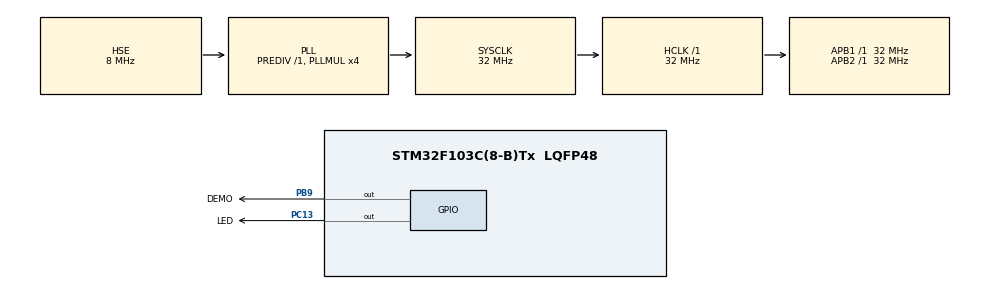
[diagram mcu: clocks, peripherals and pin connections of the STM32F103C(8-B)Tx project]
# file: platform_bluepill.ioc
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Mcu.Family=STM32F1
Mcu.Name=STM32F103C(8-B)Tx
Mcu.Package=LQFP48
NVIC.PriorityGroup=NVIC_PRIORITYGROUP_4
NVIC.TIM1_UP_IRQn=true\:0\:0\:false\:false\:true\:true\:true
PA13.Mode=Serial_Wire
PA13.Signal=SYS_JTMS-SWDIO
PA14.Mode=Serial_Wire
PA14.Signal=SYS_JTCK-SWCLK
PB9.GPIO_Label=DEMO
PB9.GPIO_ModeDefaultOutputPP=GPIO_MODE_OUTPUT_OD
PB9.GPIO_Speed=GPIO_SPEED_FREQ_HIGH
PB9.Signal=GPIO_Output
PC13-TAMPER-RTC.GPIO_Label=LED
PC13-TAMPER-RTC.GPIO_Speed=GPIO_SPEED_FREQ_LOW
PC13-TAMPER-RTC.Signal=GPIO_Output
PC14-OSC32_IN.Mode=LSE-External-Oscillator
PC14-OSC32_IN.Signal=RCC_OSC32_IN
PC15-OSC32_OUT.Mode=LSE-External-Oscillator
PC15-OSC32_OUT.Signal=RCC_OSC32_OUT
PD0-OSC_IN.Mode=HSE-External-Oscillator
PD0-OSC_IN.Signal=RCC_OSC_IN
PD1-OSC_OUT.Mode=HSE-External-Oscillator
PD1-OSC_OUT.Signal=RCC_OSC_OUT
ProjectManager.HeapSize=0x200
ProjectManager.StackSize=0x400
ProjectManager.TargetToolchain=Makefile
RCC.AHBFreq_Value=32000000
RCC.APB1Freq_Value=32000000
RCC.APB1TimFreq_Value=32000000
RCC.APB2Freq_Value=32000000
RCC.APB2TimFreq_Value=32000000
RCC.HCLKFreq_Value=32000000
RCC.PLLMUL=RCC_PLL_MUL4
RCC.PLLSourceVirtual=RCC_PLLSOURCE_HSE
RCC.SYSCLKFreq_VALUE=32000000
RCC.SYSCLKSource=RCC_SYSCLKSOURCE_PLLCLK
RCC.USBFreq_Value=32000000
TIM1.Period=61 - 3
TIM1.Prescaler=32
VP_TIM1_VS_ClockSourceINT.Mode=Internal
board=custom

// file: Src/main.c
/* USER CODE BEGIN Header */
/**
  ******************************************************************************
  * @file           : main.c
  * @brief          : Main program body
  ******************************************************************************
  * @attention
  *
  * <h2><center>&copy; Copyright (c) 2020 STMicroelectronics.
  * All rights reserved.</center></h2>
  *
  * This software component is licensed by ST under BSD 3-Clause license,
  * the "License"; You may not use this file except in compliance with the
  * License. You may obtain a copy of the License at:
  *                        opensource.org/licenses/BSD-3-Clause
  *
  ******************************************************************************
  */
/* USER CODE END Header */

#include "main.h"

TIM_HandleTypeDef htim1;

void SystemClock_Config(void);
static void MX_GPIO_Init(void);
static void MX_TIM1_Init(void);
/* USER CODE BEGIN PFP */

uint8_t handle_tick();
void init_render();

/* USER CODE END PFP */

/* USER CODE BEGIN 0 */
void HAL_TIM_PeriodElapsedCallback(TIM_HandleTypeDef *htim) {
  HAL_GPIO_TogglePin(DEMO_GPIO_Port, DEMO_Pin);

  if(handle_tick() > 0) {
    HAL_GPIO_WritePin(LED_GPIO_Port, LED_Pin, GPIO_PIN_SET);
  } else {
    HAL_GPIO_WritePin(LED_GPIO_Port, LED_Pin, GPIO_PIN_RESET);
  }
}
/* USER CODE END 0 */

int main(void)
{

  /* MCU Configuration--------------------------------------------------------*/

  /* Reset of all peripherals, Initializes the Flash interface and the Systick. */
  HAL_Init();

  /* Configure the system clock */
  SystemClock_Config();

  /* Initialize all configured peripherals */
  MX_GPIO_Init();
  MX_TIM1_Init();
  /* USER CODE BEGIN 2 */

  init_render();

  HAL_TIM_Base_Start_IT(&htim1);

  /* USER CODE END 2 */

  /* Infinite loop */
  while (1)
  {

    /* USER CODE BEGIN 3 */
    /*
    HAL_GPIO_WritePin(LED_GPIO_Port, LED_Pin, GPIO_PIN_SET);
    HAL_Delay(100);
    HAL_GPIO_WritePin(LED_GPIO_Port, LED_Pin, GPIO_PIN_RESET);
    HAL_Delay(100);
    */
  }
  /* USER CODE END 3 */
}

void SystemClock_Config(void)
{
  RCC_OscInitTypeDef RCC_OscInitStruct = {0};
  RCC_ClkInitTypeDef RCC_ClkInitStruct = {0};

  /** Initializes the CPU, AHB and APB busses clocks
  */
  RCC_OscInitStruct.OscillatorType = RCC_OSCILLATORTYPE_HSE;
  RCC_OscInitStruct.HSEState = RCC_HSE_ON;
  RCC_OscInitStruct.HSEPredivValue = RCC_HSE_PREDIV_DIV1;
  RCC_OscInitStruct.HSIState = RCC_HSI_ON;
  RCC_OscInitStruct.PLL.PLLState = RCC_PLL_ON;
  RCC_OscInitStruct.PLL.PLLSource = RCC_PLLSOURCE_HSE;
  RCC_OscInitStruct.PLL.PLLMUL = RCC_PLL_MUL4;
  if (HAL_RCC_OscConfig(&RCC_OscInitStruct) != HAL_OK)
  {
    Error_Handler();
  }
  /** Initializes the CPU, AHB and APB busses clocks
  */
  RCC_ClkInitStruct.ClockType = RCC_CLOCKTYPE_HCLK|RCC_CLOCKTYPE_SYSCLK
                              |RCC_CLOCKTYPE_PCLK1|RCC_CLOCKTYPE_PCLK2;
  RCC_ClkInitStruct.SYSCLKSource = RCC_SYSCLKSOURCE_PLLCLK;
  RCC_ClkInitStruct.AHBCLKDivider = RCC_SYSCLK_DIV1;
  RCC_ClkInitStruct.APB1CLKDivider = RCC_HCLK_DIV1;
  RCC_ClkInitStruct.APB2CLKDivider = RCC_HCLK_DIV1;

  if (HAL_RCC_ClockConfig(&RCC_ClkInitStruct, FLASH_LATENCY_1) != HAL_OK)
  {
    Error_Handler();
  }
}

static void MX_TIM1_Init(void)
{

  TIM_ClockConfigTypeDef sClockSourceConfig = {0};
  TIM_MasterConfigTypeDef sMasterConfig = {0};

  htim1.Instance = TIM1;
  htim1.Init.Prescaler = 32;
  htim1.Init.CounterMode = TIM_COUNTERMODE_UP;
  htim1.Init.Period = 61 - 3;
  htim1.Init.ClockDivision = TIM_CLOCKDIVISION_DIV1;
  htim1.Init.RepetitionCounter = 0;
  htim1.Init.AutoReloadPreload = TIM_AUTORELOAD_PRELOAD_DISABLE;
  if (HAL_TIM_Base_Init(&htim1) != HAL_OK)
  {
    Error_Handler();
  }
  sClockSourceConfig.ClockSource = TIM_CLOCKSOURCE_INTERNAL;
  if (HAL_TIM_ConfigClockSource(&htim1, &sClockSourceConfig) != HAL_OK)
  {
    Error_Handler();
  }
  sMasterConfig.MasterOutputTrigger = TIM_TRGO_RESET;
  sMasterConfig.MasterSlaveMode = TIM_MASTERSLAVEMODE_DISABLE;
  if (HAL_TIMEx_MasterConfigSynchronization(&htim1, &sMasterConfig) != HAL_OK)
  {
    Error_Handler();
  }

}

static void MX_GPIO_Init(void)
{
  GPIO_InitTypeDef GPIO_InitStruct = {0};

  /* GPIO Ports Clock Enable */
  __HAL_RCC_GPIOC_CLK_ENABLE();
  __HAL_RCC_GPIOD_CLK_ENABLE();
  __HAL_RCC_GPIOA_CLK_ENABLE();
  __HAL_RCC_GPIOB_CLK_ENABLE();

  /*Configure GPIO pin Output Level */
  HAL_GPIO_WritePin(LED_GPIO_Port, LED_Pin, GPIO_PIN_RESET);

  /*Configure GPIO pin Output Level */
  HAL_GPIO_WritePin(DEMO_GPIO_Port, DEMO_Pin, GPIO_PIN_RESET);

  /*Configure GPIO pin : LED_Pin */
  GPIO_InitStruct.Pin = LED_Pin;
  GPIO_InitStruct.Mode = GPIO_MODE_OUTPUT_PP;
  GPIO_InitStruct.Pull = GPIO_NOPULL;
  GPIO_InitStruct.Speed = GPIO_SPEED_FREQ_LOW;
  HAL_GPIO_Init(LED_GPIO_Port, &GPIO_InitStruct);

  /*Configure GPIO pin : DEMO_Pin */
  GPIO_InitStruct.Pin = DEMO_Pin;
  GPIO_InitStruct.Mode = GPIO_MODE_OUTPUT_OD;
  GPIO_InitStruct.Pull = GPIO_NOPULL;
  GPIO_InitStruct.Speed = GPIO_SPEED_FREQ_HIGH;
  HAL_GPIO_Init(DEMO_GPIO_Port, &GPIO_InitStruct);

}

void Error_Handler(void)
{
}

/************************ (C) COPYRIGHT STMicroelectronics *****END OF FILE****/
